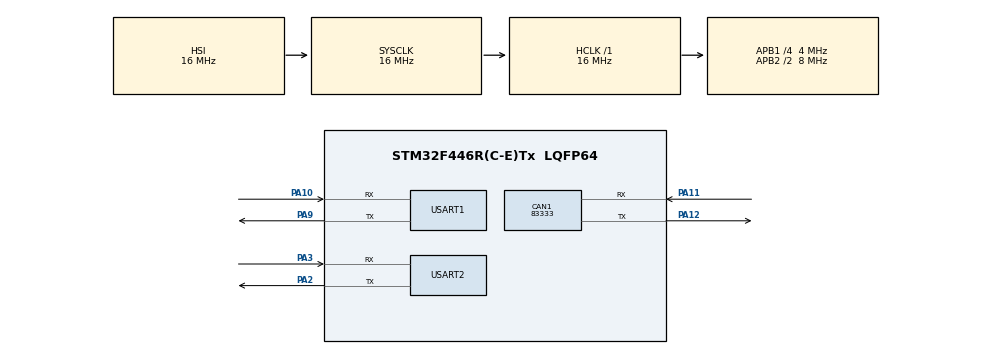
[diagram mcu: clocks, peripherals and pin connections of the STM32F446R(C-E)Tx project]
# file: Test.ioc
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CAN1.CalculateBaudRate=83333
CAN1.CalculateTimeBit=12000
CAN1.CalculateTimeQuantum=4000.0
FREERTOS.Tasks01=defaultTask,24,128,StartDefaultTask,Default,NULL,Dynamic,NULL,NULL
Mcu.Family=STM32F4
Mcu.Name=STM32F446R(C-E)Tx
Mcu.Package=LQFP64
NVIC.CAN1_RX0_IRQn=true\:5\:0\:false\:false\:true\:true\:true\:true\:true
NVIC.PriorityGroup=NVIC_PRIORITYGROUP_4
NVIC.USART2_IRQn=true\:5\:0\:false\:false\:true\:true\:true\:true\:true
PA10.Mode=Asynchronous
PA10.Signal=USART1_RX
PA11.Mode=CAN_Activate
PA11.Signal=CAN1_RX
PA12.Mode=CAN_Activate
PA12.Signal=CAN1_TX
PA2.Mode=Asynchronous
PA2.Signal=USART2_TX
PA3.Mode=Asynchronous
PA3.Signal=USART2_RX
PA9.Mode=Asynchronous
PA9.Signal=USART1_TX
PC0.Signal=ADCx_IN10
PC1.Signal=ADCx_IN11
ProjectManager.HeapSize=0x200
ProjectManager.StackSize=0x400
ProjectManager.TargetToolchain=STM32CubeIDE
RCC.AHBFreq_Value=16000000
RCC.APB1CLKDivider=RCC_HCLK_DIV4
RCC.APB1Freq_Value=4000000
RCC.APB1TimFreq_Value=8000000
RCC.APB2CLKDivider=RCC_HCLK_DIV2
RCC.APB2Freq_Value=8000000
RCC.APB2TimFreq_Value=16000000
RCC.CortexFreq_Value=16000000
RCC.HCLKFreq_Value=16000000
RCC.PLLM=8
RCC.PLLN=180
RCC.SYSCLKFreq_VALUE=16000000
RCC.USBFreq_Value=180000000
RCC.VCOOutputFreq_Value=360000000
SH.ADCx_IN10.0=ADC1_IN10
SH.ADCx_IN11.0=ADC1_IN11
USART1.VirtualMode=VM_ASYNC
USART2.VirtualMode=VM_ASYNC
VP_FREERTOS_VS_CMSIS_V2.Mode=CMSIS_V2
board=custom

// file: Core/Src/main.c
/* USER CODE BEGIN Header */
/**
  ******************************************************************************
  * @file           : main.c
  * @brief          : Main program body
  ******************************************************************************
  * @attention
  *
  * Copyright (c) 2023 STMicroelectronics.
  * All rights reserved.
  *
  * This software is licensed under terms that can be found in the LICENSE file
  * in the root directory of this software component.
  * If no LICENSE file comes with this software, it is provided AS-IS.
  *
  ******************************************************************************
  */
/* USER CODE END Header */
#include "main.h"
#include "cmsis_os.h"

CAN_HandleTypeDef hcan1;

UART_HandleTypeDef huart1;
UART_HandleTypeDef huart2;

/* Definitions for defaultTask */
osThreadId_t defaultTaskHandle;
const osThreadAttr_t defaultTask_attributes = {
  .name = "defaultTask",
  .stack_size = 128 * 4,
  .priority = (osPriority_t) osPriorityNormal,
};

void SystemClock_Config(void);
static void MX_GPIO_Init(void);
static void MX_USART2_UART_Init(void);
static void MX_USART1_UART_Init(void);
static void MX_CAN1_Init(void);
void StartDefaultTask(void *argument);

/* USER CODE BEGIN 0 */
/* USER CODE BEGIN 0 */
uint8_t rx_buff[10];
/* USER CODE END 0 */

int main(void)
{

  /* MCU Configuration--------------------------------------------------------*/

  /* Reset of all peripherals, Initializes the Flash interface and the Systick. */
  HAL_Init();

  /* Configure the system clock */
  SystemClock_Config();

  /* Initialize all configured peripherals */
  MX_GPIO_Init();
  MX_USART2_UART_Init();
  MX_USART1_UART_Init();
  MX_CAN1_Init();
  /* USER CODE BEGIN 2 */
  /* USER CODE BEGIN 2 */
  HAL_UART_Receive_IT(&huart1, rx_buff, 10);
  /* USER CODE END 2 */

  /* Init scheduler */
  osKernelInitialize();

  /* Create the thread(s) */
  /* creation of defaultTask */
  defaultTaskHandle = osThreadNew(StartDefaultTask, NULL, &defaultTask_attributes);

  /* Start scheduler */
  osKernelStart();

  /* We should never get here as control is now taken by the scheduler */
  /* Infinite loop */
  while (1)
  {

  }
}

void SystemClock_Config(void)
{
  RCC_OscInitTypeDef RCC_OscInitStruct = {0};
  RCC_ClkInitTypeDef RCC_ClkInitStruct = {0};

  /** Configure the main internal regulator output voltage
  */
  __HAL_RCC_PWR_CLK_ENABLE();
  __HAL_PWR_VOLTAGESCALING_CONFIG(PWR_REGULATOR_VOLTAGE_SCALE3);

  /** Initializes the RCC Oscillators according to the specified parameters
  * in the RCC_OscInitTypeDef structure.
  */
  RCC_OscInitStruct.OscillatorType = RCC_OSCILLATORTYPE_HSI;
  RCC_OscInitStruct.HSIState = RCC_HSI_ON;
  RCC_OscInitStruct.HSICalibrationValue = RCC_HSICALIBRATION_DEFAULT;
  RCC_OscInitStruct.PLL.PLLState = RCC_PLL_NONE;
  if (HAL_RCC_OscConfig(&RCC_OscInitStruct) != HAL_OK)
  {
    Error_Handler();
  }

  /** Initializes the CPU, AHB and APB buses clocks
  */
  RCC_ClkInitStruct.ClockType = RCC_CLOCKTYPE_HCLK|RCC_CLOCKTYPE_SYSCLK
                              |RCC_CLOCKTYPE_PCLK1|RCC_CLOCKTYPE_PCLK2;
  RCC_ClkInitStruct.SYSCLKSource = RCC_SYSCLKSOURCE_HSI;
  RCC_ClkInitStruct.AHBCLKDivider = RCC_SYSCLK_DIV1;
  RCC_ClkInitStruct.APB1CLKDivider = RCC_HCLK_DIV4;
  RCC_ClkInitStruct.APB2CLKDivider = RCC_HCLK_DIV2;

  if (HAL_RCC_ClockConfig(&RCC_ClkInitStruct, FLASH_LATENCY_0) != HAL_OK)
  {
    Error_Handler();
  }
}

static void MX_CAN1_Init(void)
{

  hcan1.Instance = CAN1;
  hcan1.Init.Prescaler = 16;
  hcan1.Init.Mode = CAN_MODE_NORMAL;
  hcan1.Init.SyncJumpWidth = CAN_SJW_1TQ;
  hcan1.Init.TimeSeg1 = CAN_BS1_1TQ;
  hcan1.Init.TimeSeg2 = CAN_BS2_1TQ;
  hcan1.Init.TimeTriggeredMode = DISABLE;
  hcan1.Init.AutoBusOff = DISABLE;
  hcan1.Init.AutoWakeUp = DISABLE;
  hcan1.Init.AutoRetransmission = DISABLE;
  hcan1.Init.ReceiveFifoLocked = DISABLE;
  hcan1.Init.TransmitFifoPriority = DISABLE;
  if (HAL_CAN_Init(&hcan1) != HAL_OK)
  {
    Error_Handler();
  }

}

static void MX_USART1_UART_Init(void)
{

  huart1.Instance = USART1;
  huart1.Init.BaudRate = 115200;
  huart1.Init.WordLength = UART_WORDLENGTH_8B;
  huart1.Init.StopBits = UART_STOPBITS_1;
  huart1.Init.Parity = UART_PARITY_NONE;
  huart1.Init.Mode = UART_MODE_TX_RX;
  huart1.Init.HwFlowCtl = UART_HWCONTROL_NONE;
  huart1.Init.OverSampling = UART_OVERSAMPLING_16;
  if (HAL_UART_Init(&huart1) != HAL_OK)
  {
    Error_Handler();
  }

}

static void MX_USART2_UART_Init(void)
{

  huart2.Instance = USART2;
  huart2.Init.BaudRate = 115200;
  huart2.Init.WordLength = UART_WORDLENGTH_8B;
  huart2.Init.StopBits = UART_STOPBITS_1;
  huart2.Init.Parity = UART_PARITY_NONE;
  huart2.Init.Mode = UART_MODE_TX_RX;
  huart2.Init.HwFlowCtl = UART_HWCONTROL_NONE;
  huart2.Init.OverSampling = UART_OVERSAMPLING_16;
  if (HAL_UART_Init(&huart2) != HAL_OK)
  {
    Error_Handler();
  }

}

static void MX_GPIO_Init(void)
{
  GPIO_InitTypeDef GPIO_InitStruct = {0};

  /* GPIO Ports Clock Enable */
  __HAL_RCC_GPIOC_CLK_ENABLE();
  __HAL_RCC_GPIOA_CLK_ENABLE();

  /*Configure GPIO pins : PC0 PC1 */
  GPIO_InitStruct.Pin = GPIO_PIN_0|GPIO_PIN_1;
  GPIO_InitStruct.Mode = GPIO_MODE_ANALOG;
  GPIO_InitStruct.Pull = GPIO_NOPULL;
  HAL_GPIO_Init(GPIOC, &GPIO_InitStruct);

}

void StartDefaultTask(void *argument)
{
  for(;;)
  {
    osDelay(1);
  }
}

void Error_Handler(void)
{
  __disable_irq();
  while (1)
  {
  }
}
